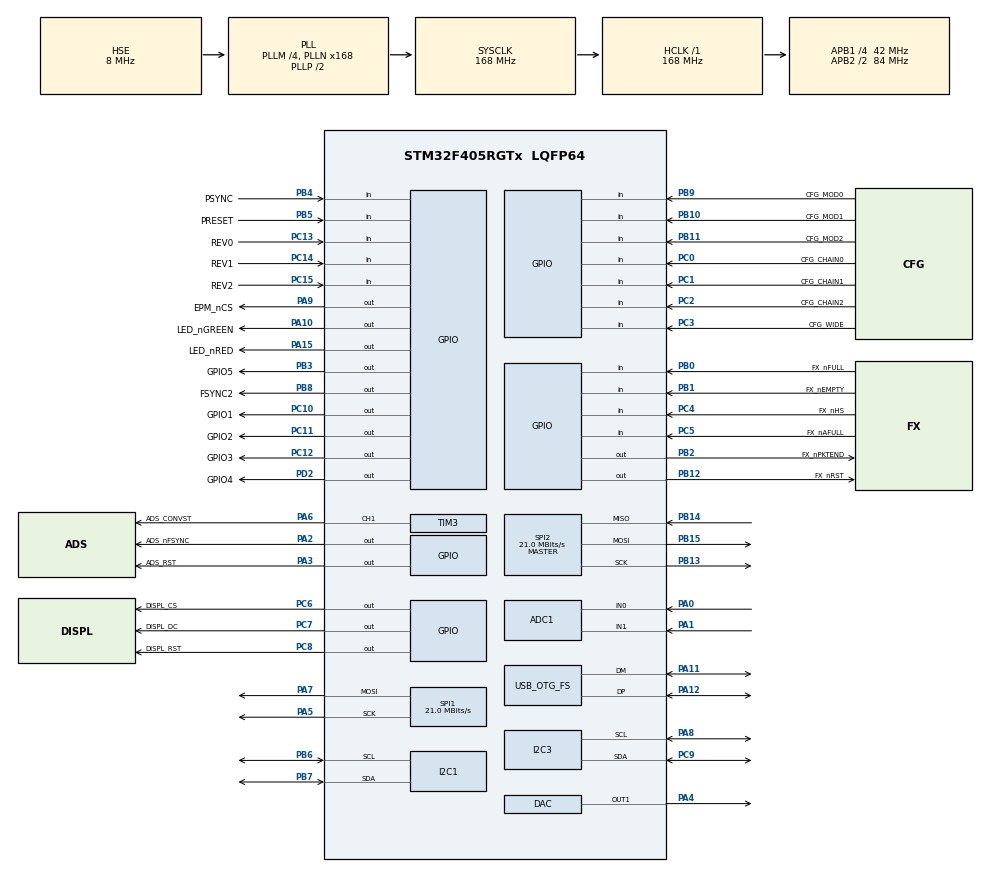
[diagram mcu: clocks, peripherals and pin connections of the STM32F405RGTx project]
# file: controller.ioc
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ADC1.Channel-0\#ChannelRegularConversion=ADC_CHANNEL_0
ADC1.Channel-1\#ChannelRegularConversion=ADC_CHANNEL_1
ADC1.Channel-2\#ChannelRegularConversion=ADC_CHANNEL_TEMPSENSOR
ADC1.Channel-3\#ChannelRegularConversion=ADC_CHANNEL_0
ADC1.NbrOfConversion=4
ADC1.NbrOfConversionFlag=1
ADC1.Rank-0\#ChannelRegularConversion=1
ADC1.Rank-1\#ChannelRegularConversion=2
ADC1.Rank-2\#ChannelRegularConversion=3
ADC1.Rank-3\#ChannelRegularConversion=4
ADC1.SamplingTime-0\#ChannelRegularConversion=ADC_SAMPLETIME_480CYCLES
ADC1.SamplingTime-1\#ChannelRegularConversion=ADC_SAMPLETIME_480CYCLES
ADC1.SamplingTime-2\#ChannelRegularConversion=ADC_SAMPLETIME_480CYCLES
ADC1.SamplingTime-3\#ChannelRegularConversion=ADC_SAMPLETIME_480CYCLES
ADC1.master=1
Dma.Request0=SPI1_TX
Dma.SPI1_TX.0.Direction=DMA_MEMORY_TO_PERIPH
Dma.SPI1_TX.0.FIFOMode=DMA_FIFOMODE_DISABLE
Dma.SPI1_TX.0.Instance=DMA2_Stream3
Dma.SPI1_TX.0.MemDataAlignment=DMA_MDATAALIGN_HALFWORD
Dma.SPI1_TX.0.MemInc=DMA_MINC_ENABLE
Dma.SPI1_TX.0.Mode=DMA_NORMAL
Dma.SPI1_TX.0.PeriphDataAlignment=DMA_PDATAALIGN_HALFWORD
Dma.SPI1_TX.0.PeriphInc=DMA_PINC_DISABLE
Dma.SPI1_TX.0.Priority=DMA_PRIORITY_LOW
Mcu.Family=STM32F4
Mcu.Name=STM32F405RGTx
Mcu.Package=LQFP64
NVIC.DMA2_Stream3_IRQn=true\:0\:0\:false\:false\:true\:false\:true
NVIC.OTG_FS_IRQn=true\:0\:0\:false\:false\:true\:false\:true
NVIC.PriorityGroup=NVIC_PRIORITYGROUP_4
PA0-WKUP.Signal=ADCx_IN0
PA1.Signal=ADCx_IN1
PA10.GPIO_Label=LED_nGREEN
PA10.GPIO_ModeDefaultOutputPP=GPIO_MODE_OUTPUT_OD
PA10.PinState=GPIO_PIN_SET
PA10.Signal=GPIO_Output
PA11.Mode=Device_Only
PA11.Signal=USB_OTG_FS_DM
PA12.Mode=Device_Only
PA12.Signal=USB_OTG_FS_DP
PA13.Mode=Serial_Wire
PA13.Signal=SYS_JTMS-SWDIO
PA14.Mode=Serial_Wire
PA14.Signal=SYS_JTCK-SWCLK
PA15.GPIO_Label=LED_nRED
PA15.PinState=GPIO_PIN_SET
PA15.Signal=GPIO_Output
PA2.GPIO_Label=ADS_nFSYNC
PA2.GPIO_Speed=GPIO_SPEED_FREQ_HIGH
PA2.PinState=GPIO_PIN_SET
PA2.Signal=GPIO_Output
PA3.GPIO_Label=ADS_RST
PA3.GPIO_Speed=GPIO_SPEED_FREQ_HIGH
PA3.PinState=GPIO_PIN_SET
PA3.Signal=GPIO_Output
PA4.Signal=COMP_DAC1_group
PA5.Mode=TX_Only_Simplex_Unidirect_Master
PA5.Signal=SPI1_SCK
PA6.GPIO_Label=ADS_CONVST
PA6.GPIO_Speed=GPIO_SPEED_FREQ_HIGH
PA6.Signal=S_TIM3_CH1
PA7.Mode=TX_Only_Simplex_Unidirect_Master
PA7.Signal=SPI1_MOSI
PA8.Mode=I2C
PA8.Signal=I2C3_SCL
PA9.GPIO_Label=EPM_nCS
PA9.GPIO_ModeDefaultOutputPP=GPIO_MODE_OUTPUT_OD
PA9.GPIO_Speed=GPIO_SPEED_FREQ_HIGH
PA9.PinState=GPIO_PIN_SET
PA9.Signal=GPIO_Output
PB0.GPIO_Label=FX_nFULL
PB0.GPIO_PuPd=GPIO_PULLDOWN
PB0.Signal=GPIO_Input
PB1.GPIO_Label=FX_nEMPTY
PB1.GPIO_PuPd=GPIO_PULLUP
PB1.Signal=GPIO_Input
PB10.GPIO_Label=CFG_MOD1
PB10.GPIO_PuPd=GPIO_PULLDOWN
PB10.Signal=GPIO_Input
PB11.GPIO_Label=CFG_MOD2
PB11.GPIO_PuPd=GPIO_PULLDOWN
PB11.Signal=GPIO_Input
PB12.GPIO_Label=FX_nRST
PB12.GPIO_Speed=GPIO_SPEED_FREQ_HIGH
PB12.PinState=GPIO_PIN_RESET
PB12.Signal=GPIO_Output
PB13.Mode=Full_Duplex_Master
PB13.Signal=SPI2_SCK
PB14.Mode=Full_Duplex_Master
PB14.Signal=SPI2_MISO
PB15.Mode=Full_Duplex_Master
PB15.Signal=SPI2_MOSI
PB2.GPIO_Label=FX_nPKTEND
PB2.GPIO_Speed=GPIO_SPEED_FREQ_HIGH
PB2.PinState=GPIO_PIN_SET
PB2.Signal=GPIO_Output
PB3.GPIO_Label=GPIO5
PB3.Signal=GPIO_Output
PB4.GPIO_Label=PSYNC
PB4.GPIO_PuPd=GPIO_PULLDOWN
PB4.Signal=GPIO_Input
PB5.GPIO_Label=PRESET
PB5.GPIO_PuPd=GPIO_PULLDOWN
PB5.Signal=GPIO_Input
PB6.Mode=I2C
PB6.Signal=I2C1_SCL
PB7.Mode=I2C
PB7.Signal=I2C1_SDA
PB8.GPIO_Label=FSYNC2
PB8.GPIO_Speed=GPIO_SPEED_FREQ_HIGH
PB8.Signal=GPIO_Output
PB9.GPIO_Label=CFG_MOD0
PB9.GPIO_PuPd=GPIO_PULLDOWN
PB9.Signal=GPIO_Input
PC0.GPIO_Label=CFG_CHAIN0
PC0.GPIO_PuPd=GPIO_PULLDOWN
PC0.Signal=GPIO_Input
PC1.GPIO_Label=CFG_CHAIN1
PC1.GPIO_PuPd=GPIO_PULLDOWN
PC1.Signal=GPIO_Input
PC10.GPIO_Label=GPIO1
PC10.Signal=GPIO_Output
PC11.GPIO_Label=GPIO2
PC11.Signal=GPIO_Output
PC12.GPIO_Label=GPIO3
PC12.Signal=GPIO_Output
PC13-ANTI_TAMP.GPIO_Label=REV0
PC13-ANTI_TAMP.GPIO_PuPd=GPIO_PULLDOWN
PC13-ANTI_TAMP.Signal=GPIO_Input
PC14-OSC32_IN.GPIO_Label=REV1
PC14-OSC32_IN.GPIO_PuPd=GPIO_PULLDOWN
PC14-OSC32_IN.Signal=GPIO_Input
PC15-OSC32_OUT.GPIO_Label=REV2
PC15-OSC32_OUT.GPIO_PuPd=GPIO_PULLDOWN
PC15-OSC32_OUT.Signal=GPIO_Input
PC2.GPIO_Label=CFG_CHAIN2
PC2.GPIO_PuPd=GPIO_PULLDOWN
PC2.Signal=GPIO_Input
PC3.GPIO_Label=CFG_WIDE
PC3.GPIO_PuPd=GPIO_PULLUP
PC3.Signal=GPIO_Input
PC4.GPIO_Label=FX_nHS
PC4.GPIO_PuPd=GPIO_PULLUP
PC4.Signal=GPIO_Input
PC5.GPIO_Label=FX_nAFULL
PC5.GPIO_PuPd=GPIO_PULLDOWN
PC5.Signal=GPIO_Input
PC6.GPIO_Label=DISPL_CS
PC6.GPIO_Speed=GPIO_SPEED_FREQ_HIGH
PC6.PinState=GPIO_PIN_SET
PC6.Signal=GPIO_Output
PC7.GPIO_Label=DISPL_DC
PC7.GPIO_Speed=GPIO_SPEED_FREQ_HIGH
PC7.Signal=GPIO_Output
PC8.GPIO_Label=DISPL_RST
PC8.GPIO_Speed=GPIO_SPEED_FREQ_HIGH
PC8.PinState=GPIO_PIN_RESET
PC8.Signal=GPIO_Output
PC9.Mode=I2C
PC9.Signal=I2C3_SDA
PD2.GPIO_Label=GPIO4
PD2.Signal=GPIO_Output
PH0-OSC_IN.Mode=HSE-External-Oscillator
PH0-OSC_IN.Signal=RCC_OSC_IN
PH1-OSC_OUT.Mode=HSE-External-Oscillator
PH1-OSC_OUT.Signal=RCC_OSC_OUT
ProjectManager.HeapSize=0x2000
ProjectManager.StackSize=0x800
ProjectManager.TargetToolchain=EWARM V8.32
RCC.48MHZClocksFreq_Value=48000000
RCC.AHBFreq_Value=168000000
RCC.APB1CLKDivider=RCC_HCLK_DIV4
RCC.APB1Freq_Value=42000000
RCC.APB1TimFreq_Value=84000000
RCC.APB2CLKDivider=RCC_HCLK_DIV2
RCC.APB2Freq_Value=84000000
RCC.APB2TimFreq_Value=168000000
RCC.CortexFreq_Value=168000000
RCC.HCLKFreq_Value=168000000
RCC.HSE_VALUE=8000000
RCC.HSI_VALUE=16000000
RCC.LSE_VALUE=32768
RCC.PLLM=4
RCC.PLLN=168
RCC.PLLQ=7
RCC.SYSCLKFreq_VALUE=168000000
RCC.SYSCLKSource=RCC_SYSCLKSOURCE_PLLCLK
RCC.VCOOutputFreq_Value=336000000
SH.ADCx_IN0.0=ADC1_IN0,IN0
SH.ADCx_IN1.0=ADC1_IN1,IN1
SH.COMP_DAC1_group.0=DAC_OUT1,DAC_OUT1
SH.S_TIM3_CH1.0=TIM3_CH1,PWM Generation1 CH1
SPI1.BaudRatePrescaler=SPI_BAUDRATEPRESCALER_4
SPI1.CLKPhase=SPI_PHASE_2EDGE
SPI1.CLKPolarity=SPI_POLARITY_HIGH
SPI1.CalculateBaudRate=21.0 MBits/s
SPI1.DataSize=SPI_DATASIZE_16BIT
SPI1.Direction=SPI_DIRECTION_2LINES
SPI1.FirstBit=SPI_FIRSTBIT_MSB
SPI1.Mode=SPI_MODE_MASTER
SPI1.VirtualType=VM_MASTER
SPI2.BaudRatePrescaler=SPI_BAUDRATEPRESCALER_2
SPI2.CalculateBaudRate=21.0 MBits/s
SPI2.Direction=SPI_DIRECTION_2LINES
SPI2.Mode=SPI_MODE_MASTER
SPI2.VirtualType=VM_MASTER
TIM3.Channel-PWM\ Generation1\ CH1=TIM_CHANNEL_1
USB_DEVICE.APP_RX_DATA_SIZE-CDC_FS=64
USB_DEVICE.APP_TX_DATA_SIZE-CDC_FS=64
USB_DEVICE.CLASS_NAME_FS=CDC
USB_DEVICE.PRODUCT_STRING_CDC_FS=TeraSense imaging controller
USB_DEVICE.VirtualMode-CDC_FS=Cdc
USB_DEVICE.VirtualModeFS=Cdc_FS
USB_OTG_FS.VirtualMode=Device_Only
VP_ADC1_TempSens_Input.Mode=IN-TempSens
VP_ADC1_Vref_Input.Mode=IN-Vrefint
VP_IWDG_VS_IWDG.Mode=IWDG_Activate
VP_TIM3_VS_ClockSourceINT.Mode=Internal
VP_TIM3_VS_OPM.Mode=OPM_bit
VP_TIM4_VS_OPM.Mode=OPM_bit
VP_USB_DEVICE_VS_USB_DEVICE_CDC_FS.Mode=CDC_FS
board=custom

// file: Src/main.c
/* USER CODE BEGIN Header */
/**
  ******************************************************************************
  * @file           : main.c
  * @brief          : Main program body
  ******************************************************************************
  * @attention
  *
  * <h2><center>&copy; Copyright (c) 2023 STMicroelectronics.
  * All rights reserved.</center></h2>
  *
  * This software component is licensed by ST under BSD 3-Clause license,
  * the "License"; You may not use this file except in compliance with the
  * License. You may obtain a copy of the License at:
  *                        opensource.org/licenses/BSD-3-Clause
  *
  ******************************************************************************
  */
/* USER CODE END Header */

#include "main.h"
#include "usb_device.h"

/* USER CODE BEGIN Includes */
#include "system.h"
#include "cli.h"
/* USER CODE END Includes */

ADC_HandleTypeDef hadc1;

DAC_HandleTypeDef hdac;

I2C_HandleTypeDef hi2c1;
I2C_HandleTypeDef hi2c3;

IWDG_HandleTypeDef hiwdg;

SPI_HandleTypeDef hspi1;
SPI_HandleTypeDef hspi2;
DMA_HandleTypeDef hdma_spi1_tx;

TIM_HandleTypeDef htim3;
TIM_HandleTypeDef htim4;

void SystemClock_Config(void);
static void MX_GPIO_Init(void);
static void MX_DMA_Init(void);
static void MX_SPI1_Init(void);
void MX_IWDG_Init(void);
static void MX_ADC1_Init(void);
static void MX_DAC_Init(void);
static void MX_I2C1_Init(void);
static void MX_I2C3_Init(void);
static void MX_SPI2_Init(void);
static void MX_TIM3_Init(void);
static void MX_TIM4_Init(void);

int main(void)
{
  /* USER CODE BEGIN 1 */
  sys_first_init();
  /* USER CODE END 1 */

  /* MCU Configuration--------------------------------------------------------*/

  /* Reset of all peripherals, Initializes the Flash interface and the Systick. */
  HAL_Init();

  /* Configure the system clock */
  SystemClock_Config();

  /* Initialize all configured peripherals */
  MX_GPIO_Init();
  MX_DMA_Init();
  MX_SPI1_Init();
  MX_USB_DEVICE_Init();
  MX_ADC1_Init();
  MX_DAC_Init();
  MX_I2C1_Init();
  MX_I2C3_Init();
  MX_SPI2_Init();
  MX_TIM3_Init();
  MX_TIM4_Init();
  /* USER CODE BEGIN 2 */
  sys_init();
  cli_init();
  /* USER CODE END 2 */

  /* Infinite loop */
  while (1)
  {

    /* USER CODE BEGIN 3 */
    sys_run();
    cli_run();
  }
  /* USER CODE END 3 */
}

void SystemClock_Config(void)
{
  RCC_OscInitTypeDef RCC_OscInitStruct = {0};
  RCC_ClkInitTypeDef RCC_ClkInitStruct = {0};

  /** Configure the main internal regulator output voltage
  */
  __HAL_RCC_PWR_CLK_ENABLE();
  __HAL_PWR_VOLTAGESCALING_CONFIG(PWR_REGULATOR_VOLTAGE_SCALE1);
  /** Initializes the CPU, AHB and APB busses clocks
  */
  RCC_OscInitStruct.OscillatorType = RCC_OSCILLATORTYPE_LSI|RCC_OSCILLATORTYPE_HSE;
  RCC_OscInitStruct.HSEState = RCC_HSE_ON;
  RCC_OscInitStruct.LSIState = RCC_LSI_ON;
  RCC_OscInitStruct.PLL.PLLState = RCC_PLL_ON;
  RCC_OscInitStruct.PLL.PLLSource = RCC_PLLSOURCE_HSE;
  RCC_OscInitStruct.PLL.PLLM = 4;
  RCC_OscInitStruct.PLL.PLLN = 168;
  RCC_OscInitStruct.PLL.PLLP = RCC_PLLP_DIV2;
  RCC_OscInitStruct.PLL.PLLQ = 7;
  if (HAL_RCC_OscConfig(&RCC_OscInitStruct) != HAL_OK)
  {
    Error_Handler();
  }
  /** Initializes the CPU, AHB and APB busses clocks
  */
  RCC_ClkInitStruct.ClockType = RCC_CLOCKTYPE_HCLK|RCC_CLOCKTYPE_SYSCLK
                              |RCC_CLOCKTYPE_PCLK1|RCC_CLOCKTYPE_PCLK2;
  RCC_ClkInitStruct.SYSCLKSource = RCC_SYSCLKSOURCE_PLLCLK;
  RCC_ClkInitStruct.AHBCLKDivider = RCC_SYSCLK_DIV1;
  RCC_ClkInitStruct.APB1CLKDivider = RCC_HCLK_DIV4;
  RCC_ClkInitStruct.APB2CLKDivider = RCC_HCLK_DIV2;

  if (HAL_RCC_ClockConfig(&RCC_ClkInitStruct, FLASH_LATENCY_5) != HAL_OK)
  {
    Error_Handler();
  }
}

static void MX_ADC1_Init(void)
{

  ADC_ChannelConfTypeDef sConfig = {0};

  /** Configure the global features of the ADC (Clock, Resolution, Data Alignment and number of conversion)
  */
  hadc1.Instance = ADC1;
  hadc1.Init.ClockPrescaler = ADC_CLOCK_SYNC_PCLK_DIV4;
  hadc1.Init.Resolution = ADC_RESOLUTION_12B;
  hadc1.Init.ScanConvMode = ENABLE;
  hadc1.Init.ContinuousConvMode = DISABLE;
  hadc1.Init.DiscontinuousConvMode = DISABLE;
  hadc1.Init.ExternalTrigConvEdge = ADC_EXTERNALTRIGCONVEDGE_NONE;
  hadc1.Init.ExternalTrigConv = ADC_SOFTWARE_START;
  hadc1.Init.DataAlign = ADC_DATAALIGN_RIGHT;
  hadc1.Init.NbrOfConversion = 4;
  hadc1.Init.DMAContinuousRequests = DISABLE;
  hadc1.Init.EOCSelection = ADC_EOC_SINGLE_CONV;
  if (HAL_ADC_Init(&hadc1) != HAL_OK)
  {
    Error_Handler();
  }
  /** Configure for the selected ADC regular channel its corresponding rank in the sequencer and its sample time.
  */
  sConfig.Channel = ADC_CHANNEL_0;
  sConfig.Rank = 1;
  sConfig.SamplingTime = ADC_SAMPLETIME_480CYCLES;
  if (HAL_ADC_ConfigChannel(&hadc1, &sConfig) != HAL_OK)
  {
    Error_Handler();
  }
  /** Configure for the selected ADC regular channel its corresponding rank in the sequencer and its sample time.
  */
  sConfig.Channel = ADC_CHANNEL_1;
  sConfig.Rank = 2;
  if (HAL_ADC_ConfigChannel(&hadc1, &sConfig) != HAL_OK)
  {
    Error_Handler();
  }
  /** Configure for the selected ADC regular channel its corresponding rank in the sequencer and its sample time.
  */
  sConfig.Channel = ADC_CHANNEL_TEMPSENSOR;
  sConfig.Rank = 3;
  if (HAL_ADC_ConfigChannel(&hadc1, &sConfig) != HAL_OK)
  {
    Error_Handler();
  }
  /** Configure for the selected ADC regular channel its corresponding rank in the sequencer and its sample time.
  */
  sConfig.Channel = ADC_CHANNEL_0;
  sConfig.Rank = 4;
  if (HAL_ADC_ConfigChannel(&hadc1, &sConfig) != HAL_OK)
  {
    Error_Handler();
  }

}

static void MX_DAC_Init(void)
{

  DAC_ChannelConfTypeDef sConfig = {0};

  /** DAC Initialization
  */
  hdac.Instance = DAC;
  if (HAL_DAC_Init(&hdac) != HAL_OK)
  {
    Error_Handler();
  }
  /** DAC channel OUT1 config
  */
  sConfig.DAC_Trigger = DAC_TRIGGER_NONE;
  sConfig.DAC_OutputBuffer = DAC_OUTPUTBUFFER_ENABLE;
  if (HAL_DAC_ConfigChannel(&hdac, &sConfig, DAC_CHANNEL_1) != HAL_OK)
  {
    Error_Handler();
  }

}

static void MX_I2C1_Init(void)
{

  hi2c1.Instance = I2C1;
  hi2c1.Init.ClockSpeed = 100000;
  hi2c1.Init.DutyCycle = I2C_DUTYCYCLE_2;
  hi2c1.Init.OwnAddress1 = 0;
  hi2c1.Init.AddressingMode = I2C_ADDRESSINGMODE_7BIT;
  hi2c1.Init.DualAddressMode = I2C_DUALADDRESS_DISABLE;
  hi2c1.Init.OwnAddress2 = 0;
  hi2c1.Init.GeneralCallMode = I2C_GENERALCALL_DISABLE;
  hi2c1.Init.NoStretchMode = I2C_NOSTRETCH_DISABLE;
  if (HAL_I2C_Init(&hi2c1) != HAL_OK)
  {
    Error_Handler();
  }

}

static void MX_I2C3_Init(void)
{

  hi2c3.Instance = I2C3;
  hi2c3.Init.ClockSpeed = 100000;
  hi2c3.Init.DutyCycle = I2C_DUTYCYCLE_2;
  hi2c3.Init.OwnAddress1 = 0;
  hi2c3.Init.AddressingMode = I2C_ADDRESSINGMODE_7BIT;
  hi2c3.Init.DualAddressMode = I2C_DUALADDRESS_DISABLE;
  hi2c3.Init.OwnAddress2 = 0;
  hi2c3.Init.GeneralCallMode = I2C_GENERALCALL_DISABLE;
  hi2c3.Init.NoStretchMode = I2C_NOSTRETCH_DISABLE;
  if (HAL_I2C_Init(&hi2c3) != HAL_OK)
  {
    Error_Handler();
  }

}

void MX_IWDG_Init(void)
{

  hiwdg.Instance = IWDG;
  hiwdg.Init.Prescaler = IWDG_PRESCALER_4;
  hiwdg.Init.Reload = 4095;
  if (HAL_IWDG_Init(&hiwdg) != HAL_OK)
  {
    Error_Handler();
  }

}

static void MX_SPI1_Init(void)
{

  /* SPI1 parameter configuration*/
  hspi1.Instance = SPI1;
  hspi1.Init.Mode = SPI_MODE_MASTER;
  hspi1.Init.Direction = SPI_DIRECTION_2LINES;
  hspi1.Init.DataSize = SPI_DATASIZE_16BIT;
  hspi1.Init.CLKPolarity = SPI_POLARITY_HIGH;
  hspi1.Init.CLKPhase = SPI_PHASE_2EDGE;
  hspi1.Init.NSS = SPI_NSS_SOFT;
  hspi1.Init.BaudRatePrescaler = SPI_BAUDRATEPRESCALER_4;
  hspi1.Init.FirstBit = SPI_FIRSTBIT_MSB;
  hspi1.Init.TIMode = SPI_TIMODE_DISABLE;
  hspi1.Init.CRCCalculation = SPI_CRCCALCULATION_DISABLE;
  hspi1.Init.CRCPolynomial = 10;
  if (HAL_SPI_Init(&hspi1) != HAL_OK)
  {
    Error_Handler();
  }

}

static void MX_SPI2_Init(void)
{

  /* SPI2 parameter configuration*/
  hspi2.Instance = SPI2;
  hspi2.Init.Mode = SPI_MODE_MASTER;
  hspi2.Init.Direction = SPI_DIRECTION_2LINES;
  hspi2.Init.DataSize = SPI_DATASIZE_8BIT;
  hspi2.Init.CLKPolarity = SPI_POLARITY_LOW;
  hspi2.Init.CLKPhase = SPI_PHASE_1EDGE;
  hspi2.Init.NSS = SPI_NSS_SOFT;
  hspi2.Init.BaudRatePrescaler = SPI_BAUDRATEPRESCALER_2;
  hspi2.Init.FirstBit = SPI_FIRSTBIT_MSB;
  hspi2.Init.TIMode = SPI_TIMODE_DISABLE;
  hspi2.Init.CRCCalculation = SPI_CRCCALCULATION_DISABLE;
  hspi2.Init.CRCPolynomial = 10;
  if (HAL_SPI_Init(&hspi2) != HAL_OK)
  {
    Error_Handler();
  }

}

static void MX_TIM3_Init(void)
{

  TIM_ClockConfigTypeDef sClockSourceConfig = {0};
  TIM_MasterConfigTypeDef sMasterConfig = {0};
  TIM_OC_InitTypeDef sConfigOC = {0};

  htim3.Instance = TIM3;
  htim3.Init.Prescaler = 0;
  htim3.Init.CounterMode = TIM_COUNTERMODE_UP;
  htim3.Init.Period = 0;
  htim3.Init.ClockDivision = TIM_CLOCKDIVISION_DIV1;
  htim3.Init.AutoReloadPreload = TIM_AUTORELOAD_PRELOAD_DISABLE;
  if (HAL_TIM_Base_Init(&htim3) != HAL_OK)
  {
    Error_Handler();
  }
  sClockSourceConfig.ClockSource = TIM_CLOCKSOURCE_INTERNAL;
  if (HAL_TIM_ConfigClockSource(&htim3, &sClockSourceConfig) != HAL_OK)
  {
    Error_Handler();
  }
  if (HAL_TIM_PWM_Init(&htim3) != HAL_OK)
  {
    Error_Handler();
  }
  if (HAL_TIM_OnePulse_Init(&htim3, TIM_OPMODE_SINGLE) != HAL_OK)
  {
    Error_Handler();
  }
  sMasterConfig.MasterOutputTrigger = TIM_TRGO_RESET;
  sMasterConfig.MasterSlaveMode = TIM_MASTERSLAVEMODE_DISABLE;
  if (HAL_TIMEx_MasterConfigSynchronization(&htim3, &sMasterConfig) != HAL_OK)
  {
    Error_Handler();
  }
  sConfigOC.OCMode = TIM_OCMODE_PWM1;
  sConfigOC.Pulse = 0;
  sConfigOC.OCPolarity = TIM_OCPOLARITY_HIGH;
  sConfigOC.OCFastMode = TIM_OCFAST_DISABLE;
  if (HAL_TIM_PWM_ConfigChannel(&htim3, &sConfigOC, TIM_CHANNEL_1) != HAL_OK)
  {
    Error_Handler();
  }
  HAL_TIM_MspPostInit(&htim3);

}

static void MX_TIM4_Init(void)
{

  htim4.Instance = TIM4;
  htim4.Init.Prescaler = 0;
  htim4.Init.CounterMode = TIM_COUNTERMODE_UP;
  htim4.Init.Period = 0;
  htim4.Init.ClockDivision = TIM_CLOCKDIVISION_DIV1;
  htim4.Init.AutoReloadPreload = TIM_AUTORELOAD_PRELOAD_DISABLE;
  if (HAL_TIM_OnePulse_Init(&htim4, TIM_OPMODE_SINGLE) != HAL_OK)
  {
    Error_Handler();
  }

}

static void MX_DMA_Init(void)
{

  /* DMA controller clock enable */
  __HAL_RCC_DMA2_CLK_ENABLE();

  /* DMA interrupt init */
  /* DMA2_Stream3_IRQn interrupt configuration */
  HAL_NVIC_SetPriority(DMA2_Stream3_IRQn, 0, 0);
  HAL_NVIC_EnableIRQ(DMA2_Stream3_IRQn);

}

static void MX_GPIO_Init(void)
{
  GPIO_InitTypeDef GPIO_InitStruct = {0};

  /* GPIO Ports Clock Enable */
  __HAL_RCC_GPIOC_CLK_ENABLE();
  __HAL_RCC_GPIOH_CLK_ENABLE();
  __HAL_RCC_GPIOA_CLK_ENABLE();
  __HAL_RCC_GPIOB_CLK_ENABLE();
  __HAL_RCC_GPIOD_CLK_ENABLE();

  /*Configure GPIO pin Output Level */
  HAL_GPIO_WritePin(GPIOA, ADS_nFSYNC_Pin|ADS_RST_Pin|EPM_nCS_Pin|LED_nGREEN_Pin
                          |LED_nRED_Pin, GPIO_PIN_SET);

  /*Configure GPIO pin Output Level */
  HAL_GPIO_WritePin(FX_nPKTEND_GPIO_Port, FX_nPKTEND_Pin, GPIO_PIN_SET);

  /*Configure GPIO pin Output Level */
  HAL_GPIO_WritePin(GPIOB, FX_nRST_Pin|GPIO5_Pin|FSYNC2_Pin, GPIO_PIN_RESET);

  /*Configure GPIO pin Output Level */
  HAL_GPIO_WritePin(DISPL_CS_GPIO_Port, DISPL_CS_Pin, GPIO_PIN_SET);

  /*Configure GPIO pin Output Level */
  HAL_GPIO_WritePin(GPIOC, DISPL_DC_Pin|DISPL_RST_Pin|GPIO1_Pin|GPIO2_Pin
                          |GPIO3_Pin, GPIO_PIN_RESET);

  /*Configure GPIO pin Output Level */
  HAL_GPIO_WritePin(GPIO4_GPIO_Port, GPIO4_Pin, GPIO_PIN_RESET);

  /*Configure GPIO pins : REV0_Pin REV1_Pin REV2_Pin CFG_CHAIN0_Pin
                           CFG_CHAIN1_Pin CFG_CHAIN2_Pin FX_nAFULL_Pin */
  GPIO_InitStruct.Pin = REV0_Pin|REV1_Pin|REV2_Pin|CFG_CHAIN0_Pin
                          |CFG_CHAIN1_Pin|CFG_CHAIN2_Pin|FX_nAFULL_Pin;
  GPIO_InitStruct.Mode = GPIO_MODE_INPUT;
  GPIO_InitStruct.Pull = GPIO_PULLDOWN;
  HAL_GPIO_Init(GPIOC, &GPIO_InitStruct);

  /*Configure GPIO pins : CFG_WIDE_Pin FX_nHS_Pin */
  GPIO_InitStruct.Pin = CFG_WIDE_Pin|FX_nHS_Pin;
  GPIO_InitStruct.Mode = GPIO_MODE_INPUT;
  GPIO_InitStruct.Pull = GPIO_PULLUP;
  HAL_GPIO_Init(GPIOC, &GPIO_InitStruct);

  /*Configure GPIO pins : ADS_nFSYNC_Pin ADS_RST_Pin */
  GPIO_InitStruct.Pin = ADS_nFSYNC_Pin|ADS_RST_Pin;
  GPIO_InitStruct.Mode = GPIO_MODE_OUTPUT_PP;
  GPIO_InitStruct.Pull = GPIO_NOPULL;
  GPIO_InitStruct.Speed = GPIO_SPEED_FREQ_HIGH;
  HAL_GPIO_Init(GPIOA, &GPIO_InitStruct);

  /*Configure GPIO pins : FX_nFULL_Pin CFG_MOD1_Pin CFG_MOD2_Pin PSYNC_Pin
                           PRESET_Pin CFG_MOD0_Pin */
  GPIO_InitStruct.Pin = FX_nFULL_Pin|CFG_MOD1_Pin|CFG_MOD2_Pin|PSYNC_Pin
                          |PRESET_Pin|CFG_MOD0_Pin;
  GPIO_InitStruct.Mode = GPIO_MODE_INPUT;
  GPIO_InitStruct.Pull = GPIO_PULLDOWN;
  HAL_GPIO_Init(GPIOB, &GPIO_InitStruct);

  /*Configure GPIO pin : FX_nEMPTY_Pin */
  GPIO_InitStruct.Pin = FX_nEMPTY_Pin;
  GPIO_InitStruct.Mode = GPIO_MODE_INPUT;
  GPIO_InitStruct.Pull = GPIO_PULLUP;
  HAL_GPIO_Init(FX_nEMPTY_GPIO_Port, &GPIO_InitStruct);

  /*Configure GPIO pins : FX_nPKTEND_Pin FX_nRST_Pin FSYNC2_Pin */
  GPIO_InitStruct.Pin = FX_nPKTEND_Pin|FX_nRST_Pin|FSYNC2_Pin;
  GPIO_InitStruct.Mode = GPIO_MODE_OUTPUT_PP;
  GPIO_InitStruct.Pull = GPIO_NOPULL;
  GPIO_InitStruct.Speed = GPIO_SPEED_FREQ_HIGH;
  HAL_GPIO_Init(GPIOB, &GPIO_InitStruct);

  /*Configure GPIO pins : DISPL_CS_Pin DISPL_DC_Pin DISPL_RST_Pin */
  GPIO_InitStruct.Pin = DISPL_CS_Pin|DISPL_DC_Pin|DISPL_RST_Pin;
  GPIO_InitStruct.Mode = GPIO_MODE_OUTPUT_PP;
  GPIO_InitStruct.Pull = GPIO_NOPULL;
  GPIO_InitStruct.Speed = GPIO_SPEED_FREQ_HIGH;
  HAL_GPIO_Init(GPIOC, &GPIO_InitStruct);

  /*Configure GPIO pin : EPM_nCS_Pin */
  GPIO_InitStruct.Pin = EPM_nCS_Pin;
  GPIO_InitStruct.Mode = GPIO_MODE_OUTPUT_OD;
  GPIO_InitStruct.Pull = GPIO_NOPULL;
  GPIO_InitStruct.Speed = GPIO_SPEED_FREQ_HIGH;
  HAL_GPIO_Init(EPM_nCS_GPIO_Port, &GPIO_InitStruct);

  /*Configure GPIO pin : LED_nGREEN_Pin */
  GPIO_InitStruct.Pin = LED_nGREEN_Pin;
  GPIO_InitStruct.Mode = GPIO_MODE_OUTPUT_OD;
  GPIO_InitStruct.Pull = GPIO_NOPULL;
  GPIO_InitStruct.Speed = GPIO_SPEED_FREQ_LOW;
  HAL_GPIO_Init(LED_nGREEN_GPIO_Port, &GPIO_InitStruct);

  /*Configure GPIO pin : LED_nRED_Pin */
  GPIO_InitStruct.Pin = LED_nRED_Pin;
  GPIO_InitStruct.Mode = GPIO_MODE_OUTPUT_PP;
  GPIO_InitStruct.Pull = GPIO_NOPULL;
  GPIO_InitStruct.Speed = GPIO_SPEED_FREQ_LOW;
  HAL_GPIO_Init(LED_nRED_GPIO_Port, &GPIO_InitStruct);

  /*Configure GPIO pins : GPIO1_Pin GPIO2_Pin GPIO3_Pin */
  GPIO_InitStruct.Pin = GPIO1_Pin|GPIO2_Pin|GPIO3_Pin;
  GPIO_InitStruct.Mode = GPIO_MODE_OUTPUT_PP;
  GPIO_InitStruct.Pull = GPIO_NOPULL;
  GPIO_InitStruct.Speed = GPIO_SPEED_FREQ_LOW;
  HAL_GPIO_Init(GPIOC, &GPIO_InitStruct);

  /*Configure GPIO pin : GPIO4_Pin */
  GPIO_InitStruct.Pin = GPIO4_Pin;
  GPIO_InitStruct.Mode = GPIO_MODE_OUTPUT_PP;
  GPIO_InitStruct.Pull = GPIO_NOPULL;
  GPIO_InitStruct.Speed = GPIO_SPEED_FREQ_LOW;
  HAL_GPIO_Init(GPIO4_GPIO_Port, &GPIO_InitStruct);

  /*Configure GPIO pin : GPIO5_Pin */
  GPIO_InitStruct.Pin = GPIO5_Pin;
  GPIO_InitStruct.Mode = GPIO_MODE_OUTPUT_PP;
  GPIO_InitStruct.Pull = GPIO_NOPULL;
  GPIO_InitStruct.Speed = GPIO_SPEED_FREQ_LOW;
  HAL_GPIO_Init(GPIO5_GPIO_Port, &GPIO_InitStruct);

}

void Error_Handler(void)
{
}

/************************ (C) COPYRIGHT STMicroelectronics *****END OF FILE****/
